# npcx9m6f register map
Registers are 8-bit, read-write, no defined reset value unless marked. A register's access mark holds for its fields unless they carry their own. Offsets are from the block's base; [hi:lo] are bit positions; {n}, {i} and the like mark numbered series.

## MIWU-1 — MULTI-INPUT WAKE-UP
Base 0x400BD000
Same registers: MIWU-1 0x400BF000, MIWU-1 0x400BF000
0x00 WKEDG1
0x01 WKAEDG1
0x0A WKPND1
0x0C WKPCL1
0x1E WKEN1
0x1F WKINEN1
0x70 WKMOD1

## PMC — POWER MANAGEMENT CONTROLLER
Base 0x4000D000
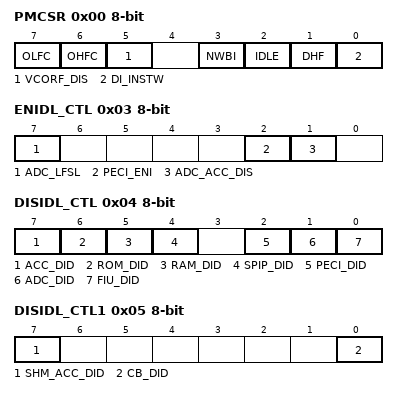
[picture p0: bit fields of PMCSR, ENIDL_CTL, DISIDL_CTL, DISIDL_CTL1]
0x00 PMCSR
  [7] OLFC, [6] OHFC, [5] VCORF_DIS, [3] NWBI, [2] IDLE, [1] DHF, [0] DI_INSTW
0x03 ENIDL_CTL
  [7] ADC_LFSL, [2] PECI_ENI, [1] ADC_ACC_DIS
0x04 DISIDL_CTL
  [7] ACC_DID, [6] ROM_DID, [5] RAM_DID, [4] SPIP_DID, [2] PECI_DID, [1] ADC_DID, [0] FIU_DID
0x05 DISIDL_CTL1
  [7] SHM_ACC_DID, [0] CB_DID
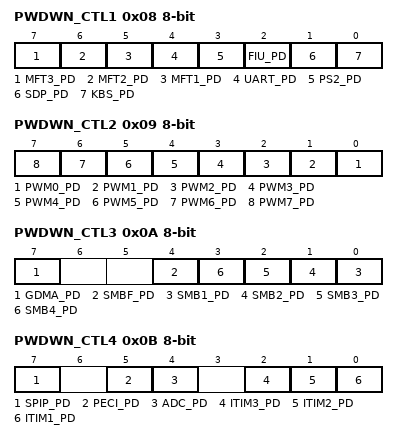
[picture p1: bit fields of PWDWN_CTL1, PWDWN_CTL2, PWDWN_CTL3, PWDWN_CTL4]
0x08 PWDWN_CTL1
  [7] MFT3_PD, [6] MFT2_PD, [5] MFT1_PD, [4] UART_PD, [3] PS2_PD, [2] FIU_PD, [1] SDP_PD, [0] KBS_PD
0x09 PWDWN_CTL2
  [n] PWM{n}_PD (n=0..7)
0x0A PWDWN_CTL3
  [7] GDMA_PD, [4] SMBF_PD, [n-1] SMB{n}_PD (n=1..4)
0x0B PWDWN_CTL4
  [7] SPIP_PD, [5] PECI_PD, [4] ADC_PD, [2] ITIM3_PD, [1] ITIM2_PD, [0] ITIM1_PD
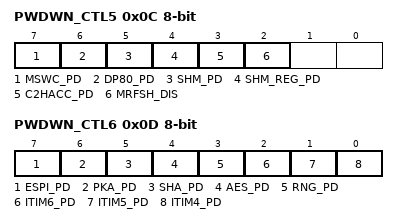
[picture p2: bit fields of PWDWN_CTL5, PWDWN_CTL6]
0x0C PWDWN_CTL5
  [7] MSWC_PD, [6] DP80_PD, [5] SHM_PD, [4] SHM_REG_PD, [3] C2HACC_PD, [2] MRFSH_DIS
0x0D PWDWN_CTL6
  [7] ESPI_PD, [6] PKA_PD, [5] SHA_PD, [4] AES_PD, [3] RNG_PD, [2] ITIM6_PD, [1] ITIM5_PD, [0] ITIM4_PD
0x0E PMC_VER
0x0F FMUL_MASK_DLY

## SIB — SIB Module
Base 0x4000E000
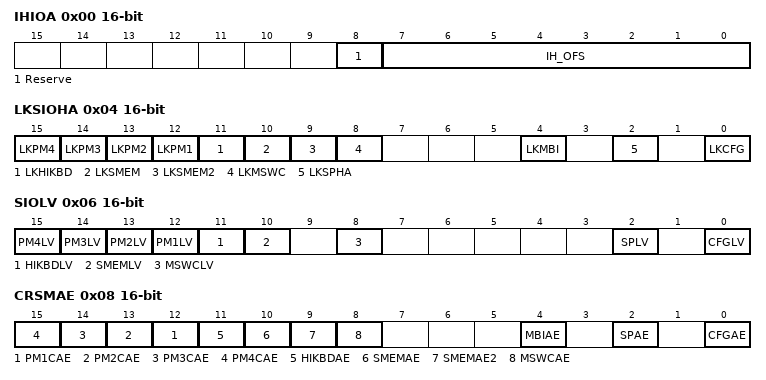
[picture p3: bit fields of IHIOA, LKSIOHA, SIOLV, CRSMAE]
0x00 IHIOA 16-bit
  [8] Reserve, [7:0] IH_OFS
0x02 IHD
0x04 LKSIOHA 16-bit
  [n+11] LKPM{n} (n=1..4), [11] LKHIKBD, [10] LKSMEM, [9] LKSMEM2, [8] LKMSWC, [4] LKMBI, [2] LKSPHA, [0] LKCFG
0x06 SIOLV 16-bit
  [n+11] PM{n}LV (n=1..4), [11] HIKBDLV, [10] SMEMLV, [8] MSWCLV, [2] SPLV, [0] CFGLV
0x08 CRSMAE 16-bit
  [n+11] PM{n}CAE (n=1..4), [11] HIKBDAE, [10] SMEMAE, [9] SMEMAE2, [8] MSWCAE, [4] MBIAE, [2] SPAE, [0] CFGAE
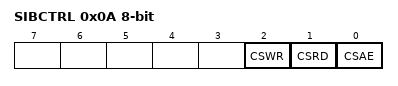
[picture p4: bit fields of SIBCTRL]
0x0A SIBCTRL
  [2] CSWR, [1] CSRD, [0] CSAE
0x0E C2H_VER

## KBC — KBC Module
Base 0x400C7000
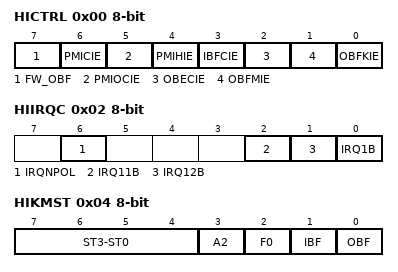
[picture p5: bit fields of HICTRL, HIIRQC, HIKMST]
0x00 HICTRL
  [7] FW_OBF, [6] PMICIE, [5] PMIOCIE, [4] PMIHIE, [3] IBFCIE, [2] OBECIE, [1] OBFMIE, [0] OBFKIE
0x02 HIIRQC
  [6] IRQNPOL, [2] IRQ11B, [1] IRQ12B, [0] IRQ1B
0x04 HIKMST
  [7:4] ST3-ST0, [3] A2, [2] F0, [1] IBF, [0] OBF
0x06 HIKDO
0x08 HIMDO
0x09 KBC_VER
0x0A HIKMDI
0x0B SHIKMDI

## PM1 — PM1 Module
Base 0x400C9000
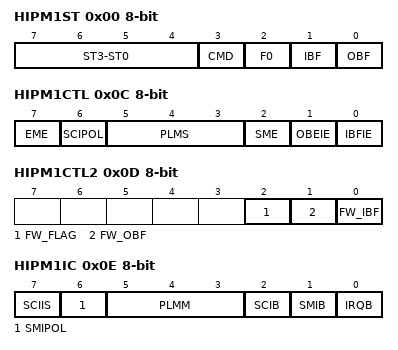
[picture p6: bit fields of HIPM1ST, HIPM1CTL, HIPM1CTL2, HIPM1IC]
0x00 HIPM1ST
  [7:4] ST3-ST0, [3] CMD, [2] F0, [1] IBF, [0] OBF
0x02 HIPM1DO
0x04 HIPM1DI
0x05 SHIPM1DI
0x06 HIPM1DOC
0x08 HIPM1DOM
0x0A HIPM1DIC
0x0C HIPM1CTL
  [7] EME, [6] SCIPOL, [5:3] PLMS, [2] SME, [1] OBEIE, [0] IBFIE
0x0D HIPM1CTL2
  [2] FW_FLAG, [1] FW_OBF, [0] FW_IBF
0x0E HIPM1IC
  [7] SCIIS, [6] SMIPOL, [5:3] PLMM, [2] SCIB, [1] SMIB, [0] IRQB
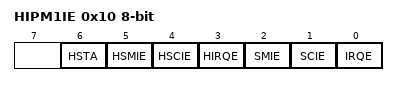
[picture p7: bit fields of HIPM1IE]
0x10 HIPM1IE
  [6] HSTA, [5] HSMIE, [4] HSCIE, [3] HIRQE, [2] SMIE, [1] SCIE, [0] IRQE
0x11 PM1_VER

## PM2 — PM2 Module
Base 0x400CB000
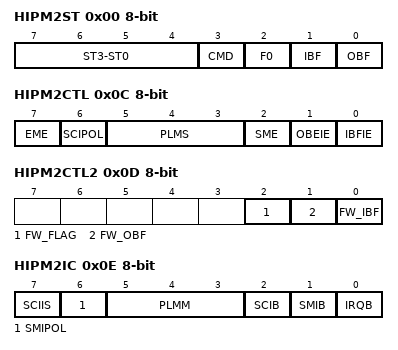
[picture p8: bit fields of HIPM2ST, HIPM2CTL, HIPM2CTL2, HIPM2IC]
0x00 HIPM2ST
  [7:4] ST3-ST0, [3] CMD, [2] F0, [1] IBF, [0] OBF
0x02 HIPM2DO
0x04 HIPM2DI
0x05 SHIPM2DI
0x06 HIPM2DOC
0x08 HIPM2DOM
0x0A HIPM2DIC
0x0C HIPM2CTL
  [7] EME, [6] SCIPOL, [5:3] PLMS, [2] SME, [1] OBEIE, [0] IBFIE
0x0D HIPM2CTL2
  [2] FW_FLAG, [1] FW_OBF, [0] FW_IBF
0x0E HIPM2IC
  [7] SCIIS, [6] SMIPOL, [5:3] PLMM, [2] SCIB, [1] SMIB, [0] IRQB
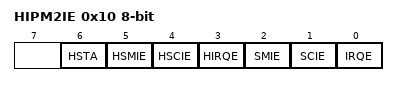
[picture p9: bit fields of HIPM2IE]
0x10 HIPM2IE
  [6] HSTA, [5] HSMIE, [4] HSCIE, [3] HIRQE, [2] SMIE, [1] SCIE, [0] IRQE
0x11 PM2_VER

## PM3 — PM3 Module
Base 0x400CD000
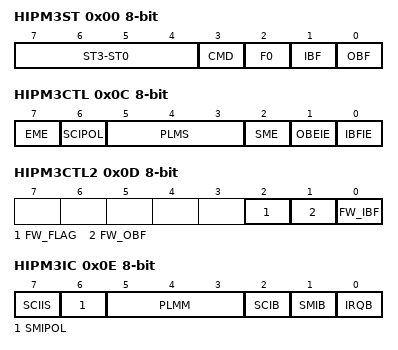
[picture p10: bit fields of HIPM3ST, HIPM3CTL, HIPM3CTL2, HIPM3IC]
0x00 HIPM3ST
  [7:4] ST3-ST0, [3] CMD, [2] F0, [1] IBF, [0] OBF
0x02 HIPM3DO
0x04 HIPM3DI
0x05 SHIPM3DI
0x06 HIPM3DOC
0x08 HIPM3DOM
0x0A HIPM3DIC
0x0C HIPM3CTL
  [7] EME, [6] SCIPOL, [5:3] PLMS, [2] SME, [1] OBEIE, [0] IBFIE
0x0D HIPM3CTL2
  [2] FW_FLAG, [1] FW_OBF, [0] FW_IBF
0x0E HIPM3IC
  [7] SCIIS, [6] SMIPOL, [5:3] PLMM, [2] SCIB, [1] SMIB, [0] IRQB
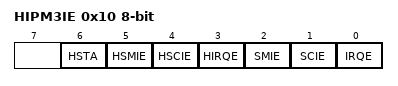
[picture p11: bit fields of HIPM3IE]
0x10 HIPM3IE
  [6] HSTA, [5] HSMIE, [4] HSCIE, [3] HIRQE, [2] SMIE, [1] SCIE, [0] IRQE
0x11 PM3_VER

## PM4 — PM4 Module
Base 0x400CF000
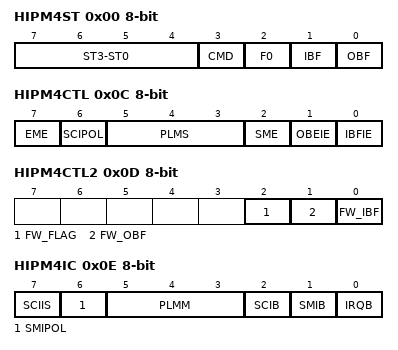
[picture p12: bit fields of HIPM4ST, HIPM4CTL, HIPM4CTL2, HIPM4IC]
0x00 HIPM4ST
  [7:4] ST3-ST0, [3] CMD, [2] F0, [1] IBF, [0] OBF
0x02 HIPM4DO
0x04 HIPM4DI
0x05 SHIPM4DI
0x06 HIPM4DOC
0x08 HIPM4DOM
0x0A HIPM4DIC
0x0C HIPM4CTL
  [7] EME, [6] SCIPOL, [5:3] PLMS, [2] SME, [1] OBEIE, [0] IBFIE
0x0D HIPM4CTL2
  [2] FW_FLAG, [1] FW_OBF, [0] FW_IBF
0x0E HIPM4IC
  [7] SCIIS, [6] SMIPOL, [5:3] PLMM, [2] SCIB, [1] SMIB, [0] IRQB
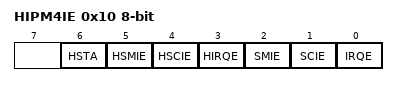
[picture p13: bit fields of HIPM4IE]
0x10 HIPM4IE
  [6] HSTA, [5] HSMIE, [4] HSCIE, [3] HIRQE, [2] SMIE, [1] SCIE, [0] IRQE
0x11 PM4_VER
